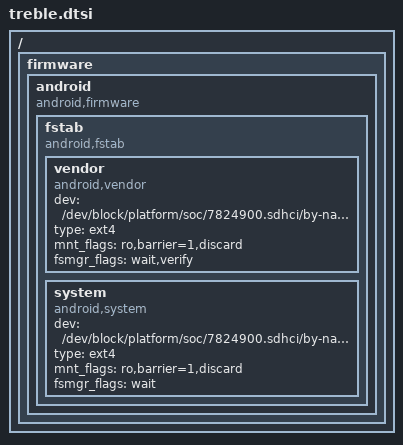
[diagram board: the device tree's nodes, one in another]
/ {
	firmware {

		android {
			compatible = "android,firmware";

			fstab {
				compatible = "android,fstab";

				vendor {
					compatible = "android,vendor";
					dev = "/dev/block/platform/soc/7824900.sdhci/by-name/cust";
					type = "ext4";
					mnt_flags = "ro,barrier=1,discard";
					fsmgr_flags = "wait,verify";
					status = "ok";
				};

				system {
					compatible = "android,system";
					dev = "/dev/block/platform/soc/7824900.sdhci/by-name/system";
					type = "ext4";
					mnt_flags = "ro,barrier=1,discard";
					fsmgr_flags = "wait";
					status = "ok";
				};
			};
		};
	};
};
